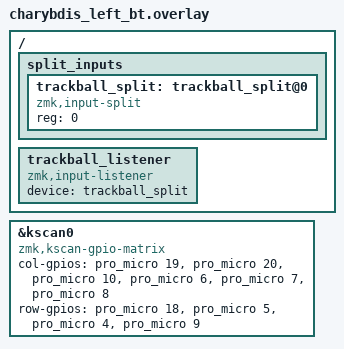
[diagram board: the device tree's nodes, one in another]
#include "../charybdis_common/charybdis.dtsi"

/ {
    split_inputs {
        #address-cells = <1>;
        #size-cells = <0>;

        trackball_split: trackball_split@0 {
            compatible = "zmk,input-split";
            reg = <0>;
        };
    };

    trackball_listener: trackball_listener {
        compatible = "zmk,input-listener";
        device = <&trackball_split>;
        status = "okay";
    };
};

// Layer-dependent precision and scroll processing runs on the central.
#include "../../config/trackball/charybdis_pointer.dtsi"

&kscan0 {
	compatible = "zmk,kscan-gpio-matrix";
	
	col-gpios
		= <&pro_micro 19 (GPIO_ACTIVE_HIGH | GPIO_PULL_DOWN)>
		, <&pro_micro 20 (GPIO_ACTIVE_HIGH | GPIO_PULL_DOWN)>
		, <&pro_micro 10 (GPIO_ACTIVE_HIGH | GPIO_PULL_DOWN)>
		, <&pro_micro 6 (GPIO_ACTIVE_HIGH | GPIO_PULL_DOWN)>
		, <&pro_micro 7 (GPIO_ACTIVE_HIGH | GPIO_PULL_DOWN)>
		, <&pro_micro 8 (GPIO_ACTIVE_HIGH | GPIO_PULL_DOWN)>
		;

	row-gpios
		= <&pro_micro 18 GPIO_ACTIVE_HIGH>
		, <&pro_micro 5 GPIO_ACTIVE_HIGH>
		, <&pro_micro 4 GPIO_ACTIVE_HIGH>
		, <&pro_micro 9 GPIO_ACTIVE_HIGH>
		;
};
